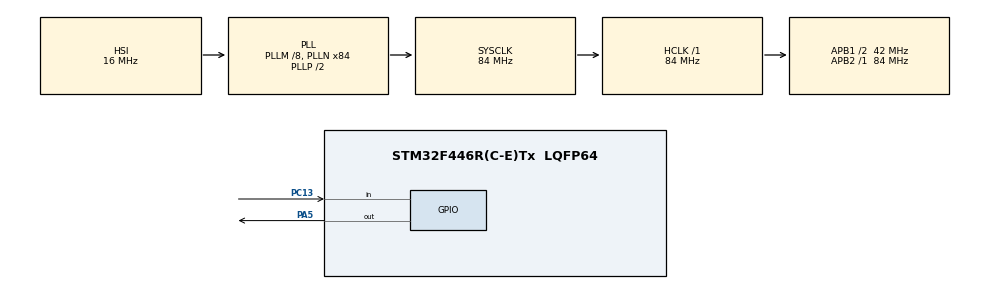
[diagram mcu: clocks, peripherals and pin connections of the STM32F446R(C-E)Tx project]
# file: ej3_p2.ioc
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Mcu.Family=STM32F4
Mcu.Name=STM32F446R(C-E)Tx
Mcu.Package=LQFP64
NVIC.PriorityGroup=NVIC_PRIORITYGROUP_4
PA13.Mode=Serial_Wire
PA13.Signal=SYS_JTMS-SWDIO
PA14.Mode=Serial_Wire
PA14.Signal=SYS_JTCK-SWCLK
PA5.Signal=GPIO_Output
PC13.GPIO_PuPd=GPIO_PULLDOWN
PC13.Signal=GPIO_Input
PC14-OSC32_IN.Mode=LSE-External-Oscillator
PC14-OSC32_IN.Signal=RCC_OSC32_IN
PC15-OSC32_OUT.Mode=LSE-External-Oscillator
PC15-OSC32_OUT.Signal=RCC_OSC32_OUT
PH0-OSC_IN.Mode=HSE-External-Oscillator
PH0-OSC_IN.Signal=RCC_OSC_IN
PH1-OSC_OUT.Mode=HSE-External-Oscillator
PH1-OSC_OUT.Signal=RCC_OSC_OUT
ProjectManager.HeapSize=0x200
ProjectManager.StackSize=0x400
ProjectManager.TargetToolchain=STM32CubeIDE
RCC.AHBFreq_Value=84000000
RCC.APB1CLKDivider=RCC_HCLK_DIV2
RCC.APB1Freq_Value=42000000
RCC.APB1TimFreq_Value=84000000
RCC.APB2Freq_Value=84000000
RCC.APB2TimFreq_Value=84000000
RCC.CortexFreq_Value=84000000
RCC.HCLKFreq_Value=84000000
RCC.PLLM=8
RCC.PLLN=84
RCC.SYSCLKFreq_VALUE=84000000
RCC.SYSCLKSource=RCC_SYSCLKSOURCE_PLLCLK
RCC.USBFreq_Value=84000000
RCC.VCOOutputFreq_Value=168000000
board=custom

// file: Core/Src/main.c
/* USER CODE BEGIN Header */
/**
  ******************************************************************************
  * @file           : main.c
  * @brief          : Main program body
  ******************************************************************************
  * @attention
  *
  * Copyright (c) 2025 STMicroelectronics.
  * All rights reserved.
  *
  * This software is licensed under terms that can be found in the LICENSE file
  * in the root directory of this software component.
  * If no LICENSE file comes with this software, it is provided AS-IS.
  *
  ******************************************************************************
  */
/* USER CODE END Header */
#include "main.h"

/* USER CODE BEGIN PD */
#define MAX_Toggle 10

/* USER CODE END PD */

void SystemClock_Config(void);
static void MX_GPIO_Init(void);

int main(void)
{

  /* MCU Configuration--------------------------------------------------------*/

  /* Reset of all peripherals, Initializes the Flash interface and the Systick. */
  HAL_Init();

  /* Configure the system clock */
  SystemClock_Config();

  /* Initialize all configured peripherals */
  MX_GPIO_Init();
  /* USER CODE BEGIN 2 */
  delay_t The_Delay;
  uint32_t time_f[3]={1,200,100};
  uint32_t counter=0;
  uint32_t idx=0;

  delayInit(&The_Delay,time_f[0]);
  /* USER CODE END 2 */

  /* Infinite loop */
  while (1)
  {

    /* USER CODE BEGIN 3 */

	  if(!delayRead(&The_Delay)){
		counter++;
		delayInit(&The_Delay,time_f[idx]);
		HAL_GPIO_TogglePin(LD2_GPIO_Port, LD2_Pin);
		if(counter>=MAX_Toggle){						//Se realizan 10 Toggles por frecuencia
			counter=0;									//Saturacion de counter
			delayWrite(&The_Delay,time_f[idx]);
			(idx>=2)?idx=0:idx++;						//Saturacion de idx
		}
	  }

	  //Make something else during the blink

  }
  /* USER CODE END 3 */
}

void SystemClock_Config(void)
{
  RCC_OscInitTypeDef RCC_OscInitStruct = {0};
  RCC_ClkInitTypeDef RCC_ClkInitStruct = {0};

  /** Configure the main internal regulator output voltage
  */
  __HAL_RCC_PWR_CLK_ENABLE();
  __HAL_PWR_VOLTAGESCALING_CONFIG(PWR_REGULATOR_VOLTAGE_SCALE3);

  /** Initializes the RCC Oscillators according to the specified parameters
  * in the RCC_OscInitTypeDef structure.
  */
  RCC_OscInitStruct.OscillatorType = RCC_OSCILLATORTYPE_HSI;
  RCC_OscInitStruct.HSIState = RCC_HSI_ON;
  RCC_OscInitStruct.HSICalibrationValue = RCC_HSICALIBRATION_DEFAULT;
  RCC_OscInitStruct.PLL.PLLState = RCC_PLL_ON;
  RCC_OscInitStruct.PLL.PLLSource = RCC_PLLSOURCE_HSI;
  RCC_OscInitStruct.PLL.PLLM = 8;
  RCC_OscInitStruct.PLL.PLLN = 84;
  RCC_OscInitStruct.PLL.PLLP = RCC_PLLP_DIV2;
  RCC_OscInitStruct.PLL.PLLQ = 2;
  RCC_OscInitStruct.PLL.PLLR = 2;
  if (HAL_RCC_OscConfig(&RCC_OscInitStruct) != HAL_OK)
  {
    Error_Handler();
  }

  /** Initializes the CPU, AHB and APB buses clocks
  */
  RCC_ClkInitStruct.ClockType = RCC_CLOCKTYPE_HCLK|RCC_CLOCKTYPE_SYSCLK
                              |RCC_CLOCKTYPE_PCLK1|RCC_CLOCKTYPE_PCLK2;
  RCC_ClkInitStruct.SYSCLKSource = RCC_SYSCLKSOURCE_PLLCLK;
  RCC_ClkInitStruct.AHBCLKDivider = RCC_SYSCLK_DIV1;
  RCC_ClkInitStruct.APB1CLKDivider = RCC_HCLK_DIV2;
  RCC_ClkInitStruct.APB2CLKDivider = RCC_HCLK_DIV1;

  if (HAL_RCC_ClockConfig(&RCC_ClkInitStruct, FLASH_LATENCY_2) != HAL_OK)
  {
    Error_Handler();
  }
}

static void MX_GPIO_Init(void)
{
  GPIO_InitTypeDef GPIO_InitStruct = {0};

  /* GPIO Ports Clock Enable */
  __HAL_RCC_GPIOC_CLK_ENABLE();
  __HAL_RCC_GPIOH_CLK_ENABLE();
  __HAL_RCC_GPIOA_CLK_ENABLE();

  /*Configure GPIO pin Output Level */
  HAL_GPIO_WritePin(GPIOA, GPIO_PIN_5, GPIO_PIN_RESET);

  /*Configure GPIO pin : PC13 */
  GPIO_InitStruct.Pin = GPIO_PIN_13;
  GPIO_InitStruct.Mode = GPIO_MODE_INPUT;
  GPIO_InitStruct.Pull = GPIO_PULLDOWN;
  HAL_GPIO_Init(GPIOC, &GPIO_InitStruct);

  /*Configure GPIO pin : PA5 */
  GPIO_InitStruct.Pin = GPIO_PIN_5;
  GPIO_InitStruct.Mode = GPIO_MODE_OUTPUT_PP;
  GPIO_InitStruct.Pull = GPIO_NOPULL;
  GPIO_InitStruct.Speed = GPIO_SPEED_FREQ_LOW;
  HAL_GPIO_Init(GPIOA, &GPIO_InitStruct);

}

/* USER CODE BEGIN 4 */

/*Funcion para inicializar el delay*/
void delayInit( delay_t * delay, tick_t duration ){
	delay->running=false;								//asignaciones
	delay->duration=duration;
}

/*Funcion para chechear si se termino el tiempo de delay*/
bool_t delayRead( delay_t * delay ){
	if(!delay->running){
		delay->startTime= HAL_GetTick();
		delay->running=true;
	}

	if(HAL_GetTick()-delay->startTime >= delay->duration){
		delay->running=false;
	}

	return (delay->running);
}

/*Funcion para modificar el tiempo de delay*/
void delayWrite( delay_t * delay, tick_t duration ){
	delay->duration=duration;
}

/* USER CODE END 4 */

void Error_Handler(void)
{
  __disable_irq();
  while (1)
  {
  }
}
